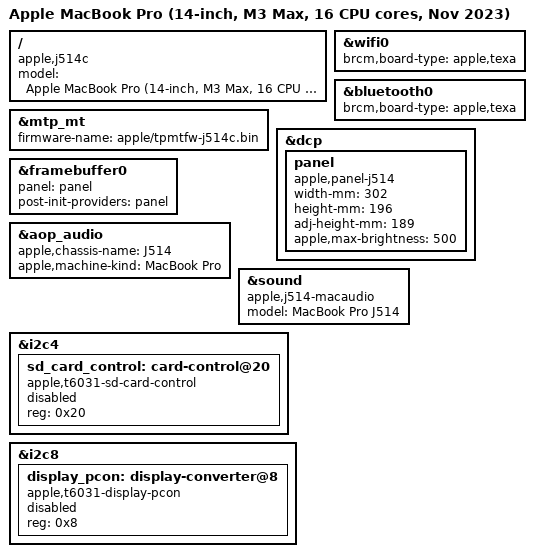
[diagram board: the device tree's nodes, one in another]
// SPDX-License-Identifier: GPL-2.0+ OR MIT
/*
 * MacBook Pro (14-inch, M3 Max, 16 CPU cores, Nov 2023)
 *
 * target-type: J514c
 *
 * Copyright The Asahi Linux Contributors
 */

/dts-v1/;

#include "t6031.dtsi"
#include "t6031-dcp.dtsi"
#include "t603x-j514-j516.dtsi"

/ {
	compatible = "apple,j514c", "apple,t6031", "apple,arm-platform";
	model = "Apple MacBook Pro (14-inch, M3 Max, 16 CPU cores, Nov 2023)";
};

&mtp_mt {
	firmware-name = "apple/tpmtfw-j514c.bin";
};

&wifi0 {
	brcm,board-type = "apple,texa";
};

&bluetooth0 {
	brcm,board-type = "apple,texa";
};

/* The J514S panel: the same chassis. Not yet read from a J514C. */
&dcp {
	panel: panel {
		compatible = "apple,panel-j514", "apple,panel-mini-led", "apple,panel";
		width-mm = <302>;
		height-mm = <196>;
		adj-height-mm = <189>;
		apple,max-brightness = <500>;
	};
};

&framebuffer0 {
	panel = <&panel>;
	post-init-providers = <&panel>;
};

&aop_audio {
	apple,chassis-name = "J514";
	apple,machine-kind = "MacBook Pro";
};

&sound {
	compatible = "apple,j514-macaudio", "apple,j314-macaudio", "apple,macaudio";
	model = "MacBook Pro J514";
};


&i2c4 {
	sd_card_control: card-control@20 {
		compatible = "apple,t6031-sd-card-control", "apple,sd-card-control";
		reg = <0x20>;
		status = "disabled";
	};
};

&i2c8 {
	display_pcon: display-converter@8 {
		compatible = "apple,t6031-display-pcon", "apple,display-pcon";
		reg = <0x8>;
		status = "disabled";
	};
};
